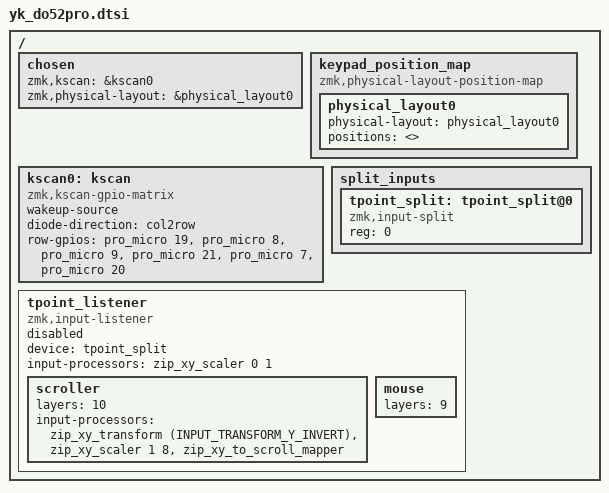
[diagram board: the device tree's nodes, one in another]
/*
 * Copyright (c) 2020 Pete Johanson
 *
 * SPDX-License-Identifier: MIT
 */

#include <dt-bindings/zmk/matrix_transform.h>

#include <physical_layouts.dtsi>
#include "yk_do52pro-layouts.dtsi"
/ {
    chosen {
       
        zmk,kscan = &kscan0;
        //zmk,matrix-transform = &default_transform;
        zmk,physical-layout = &physical_layout0;
        
    };

    keypad_position_map {
        compatible = "zmk,physical-layout-position-map";

        physical_layout0 {
            physical-layout = <&physical_layout0>;
            positions = <>;
        };
    };

    kscan0: kscan {
        compatible = "zmk,kscan-gpio-matrix";
        wakeup-source;

        diode-direction = "col2row";
        row-gpios
            = <&pro_micro 19 (GPIO_ACTIVE_HIGH | GPIO_PULL_DOWN)>
            , <&pro_micro 8 (GPIO_ACTIVE_HIGH | GPIO_PULL_DOWN)>
            , <&pro_micro 9 (GPIO_ACTIVE_HIGH | GPIO_PULL_DOWN)>
            , <&pro_micro 21 (GPIO_ACTIVE_HIGH | GPIO_PULL_DOWN)>
            , <&pro_micro 7 (GPIO_ACTIVE_HIGH | GPIO_PULL_DOWN)>
            , <&pro_micro 20 (GPIO_ACTIVE_HIGH | GPIO_PULL_DOWN)>
            ;

    };

    // TODO: per-key RGB node(s)?
};


/*
*   For ZMK Split Input Peripheral
*
*/
#include <input/processors.dtsi>
#include <zephyr/dt-bindings/input/input-event-codes.h>
#include <dt-bindings/zmk/input_transform.h>

/{
  split_inputs {
    #address-cells = <1>;
    #size-cells = <0>;
    tpoint_split: tpoint_split@0 { compatible = "zmk,input-split"; reg = <0>; };
  };
  
  // We need to add a listener to all the splits,
  // i.e., for both the central and peripheral(s).

  tpoint_listener: tpoint_listener {
        compatible = "zmk,input-listener";
        status = "disabled";
        device = <&tpoint_split>;
        input-processors = <&zip_xy_scaler 0 1>;
        scroller {
            layers = <10>;
            input-processors = <&zip_xy_transform (INPUT_TRANSFORM_Y_INVERT)>, <&zip_xy_scaler 1 8>, <&zip_xy_to_scroll_mapper>;
        };
        mouse {
            layers = <9>;
        //    input-processors = <&zip_xy_scaler 1 1>;
            
        };

  };
};


